# PIC32CM2532LS60048 register map
Vendor: Microchip Technology; Series: PIC32CMLS60; File version: 0
CPU: CM23 r0p0, selectable endian, MPU, no FPU, 2 interrupt priority bits
Registers are 32-bit, read-write, reset 0x0 unless marked. A register's access mark holds for its fields unless they carry their own. Offsets are from the block's base; [hi:lo] are bit positions; {n}, {i} and the like mark numbered series; 'fields as' and 'values as' point back to an identical list.

## CCL — Configurable Custom Logic
Base 0x42004800; register names take the prefix CCL_
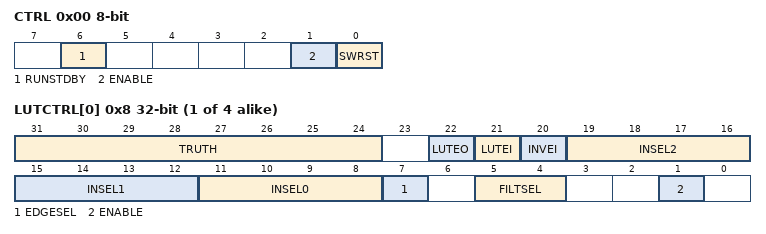
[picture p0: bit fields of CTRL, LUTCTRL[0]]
0x00 CTRL 8-bit — Control
  [6] RUNSTDBY — Run in Standby
    0=DISABLE (Generic clock is not required in standby sleep mode); 1=ENABLE (Generic clock is required in standby sleep mode)
  [1] ENABLE
    0=DISABLE (The peripheral is disabled); 1=ENABLE (The peripheral is enabled)
  [0] SWRST — Software Reset
    0=DISABLE (The peripheral is not reset); 1=ENABLE (The peripheral is reset)
{0x4+i} SEQCTRL[{i}] (i=0..1) 8-bit — SEQ Control x
  [3:0] SEQSEL — Sequential Selection
    0=DISABLE (Sequential logic is disabled); 1=DFF (D flip flop); 2=JK (JK flip flop); 3=LATCH (D latch); 4=RS (RS latch)
{0x8+4i} LUTCTRL[{i}] (i=0..3) — LUT Control x
  [31:24] TRUTH — Truth Value
  [22] LUTEO — LUT Event Output Enable
    0=DISABLE (LUT event output is disabled); 1=ENABLE (LUT event output is enabled)
  [21] LUTEI — LUT Event Input Enable
    0=DISABLE (LUT incoming event is disabled); 1=ENABLE (LUT incoming event is enabled)
  [20] INVEI — Inverted Event Input Enable
    0=NORMAL (Incoming event is not inverted); 1=INVERTED (Incoming event is inverted)
  [19:16] INSEL2 — Input Selection 2
    0=MASK (Masked input); 1=FEEDBACK (Feedback input source); 2=LINK (Linked LUT input source); 3=EVENT (Event input source); 4=IO (I/O pin input source); 5=AC (AC input source); 6=TC (TC input source); 7=ALTTC (Alternate TC input source); 8=TCC (TCC input source); 9=SERCOM (SERCOM input source); 11=ASYNCEVENT (Asynchronous event input source)
  [15:12] INSEL1 — Input Selection 1
    values as INSEL2
  [11:8] INSEL0 — Input Selection 0
    values as INSEL2
  [7] EDGESEL — Edge Selection
    0=DISABLE (Edge detector is disabled); 1=ENABLE (Edge detector is enabled)
  [5:4] FILTSEL — Filter Selection
    0=DISABLE (Filter disabled); 1=SYNCH (Synchronizer enabled); 2=FILTER (Filter enabled)
  [1] ENABLE — LUT Enable
    0=DISABLE (LUT block is disabled); 1=ENABLE (LUT block is enabled)

## CoreDebug — Debug Control Block
Base 0xE000EDF0; register names take the prefix CoreDebug_
Same registers: CoreDebug_NS 0xE002EDF0
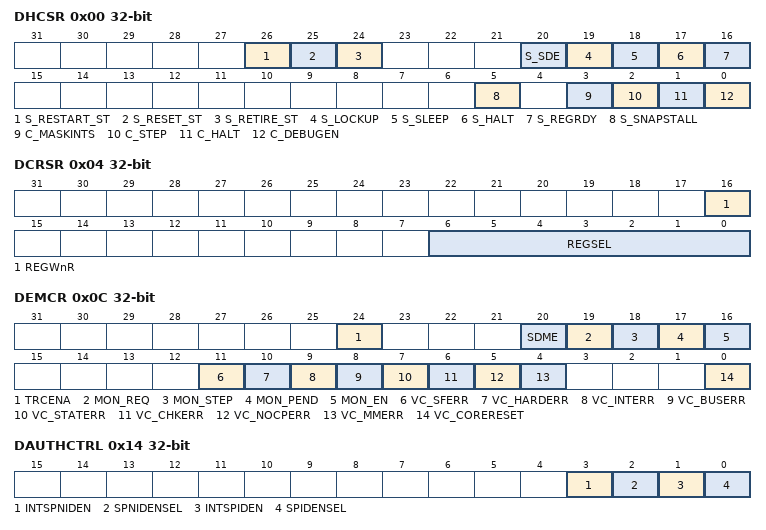
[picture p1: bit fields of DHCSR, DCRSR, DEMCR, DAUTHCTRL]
0x00 DHCSR — Debug Halting Control and Status Register
  [26] S_RESTART_ST — Restart sticky status
  [25] S_RESET_ST — Reset sticky status
  [24] S_RETIRE_ST — Retire sticky status
  [20] S_SDE — Secure debug enabled
  [19] S_LOCKUP — Lockup status
  [18] S_SLEEP — Sleeping status
  [17] S_HALT — Halted status
  [16] S_REGRDY — Register ready status
  [5] S_SNAPSTALL — Snap stall control
  [3] C_MASKINTS — Mask PendSV, SysTick and external configurable interrupts
  [2] C_STEP — Enable single step
  [1] C_HALT — Halt processor
  [0] C_DEBUGEN — Enable Halting debug
0x04 DCRSR wo — Debug Core Register Select Register
  [16] REGWnR — Register write/not-read access
  [6:0] REGSEL — Register selector
0x0C DEMCR — Debug Exception and Monitor Control Register
  [24] TRCENA — Global DWT and ITM features enable
  [20] SDME — Secure DebugMonitor enable
  [19] MON_REQ — DebugMonitor semaphore bit
  [18] MON_STEP — Enable DebugMonitor stepping
  [17] MON_PEND — DebugMonitor pending state
  [16] MON_EN — DebugMonitor enable
  [11] VC_SFERR — SecureFault exception Halting debug vector catch enable
  [10] VC_HARDERR — HardFault exception Halting debug vector catch enable
  [9] VC_INTERR — Excception entry and return faults Halting debug vector catch enable
  [8] VC_BUSERR — BusFault exception Halting debug vector catch enable
  [7] VC_STATERR — UsageFault exception state information error Halting debug vector catch enable
  [6] VC_CHKERR — UsageFault exception checking error Halting debug vector catch enable
  [5] VC_NOCPERR — UsageFault exception coprocessor access Halting debug vector catch enable
  [4] VC_MMERR — MemManage exception Halting debug vector catch enable
  [0] VC_CORERESET — Core reset Halting debug vector catch enable
0x14 DAUTHCTRL — Debug Authentication Control Register
  [3] INTSPNIDEN — Internal Secure non-invasive debug enable
  [2] SPNIDENSEL — Secure non-invasive debug enable select
  [1] INTSPIDEN — Internal Secure invasive debug enable
  [0] SPIDENSEL — Secure invasive debug enable select
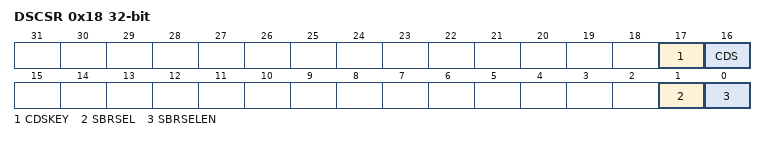
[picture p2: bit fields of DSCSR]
0x18 DSCSR — Debug Security Control and Status Register
  [17] CDSKEY — CDS field write-enable key
  [16] CDS — Current domain Secure
  [1] SBRSEL — Secure Banked register select
  [0] SBRSELEN — Secure Banked register select enable

## Notices in the file
Copyright (c) 2017 Microchip Technology Inc.
SPDX-License-Identifier: Apache-2.0
Licensed under the Apache License, Version 2.0 (the "License");
you may not use this file except in compliance with the License.
You may obtain a copy of the License at
http://www.apache.org/licenses/LICENSE-2.0
Unless required by applicable law or agreed to in writing, software
distributed under the License is distributed on an "AS IS" BASIS,
WITHOUT WARRANTIES OR CONDITIONS OF ANY KIND, either express or implied.
See the License for the specific language governing permissions and
limitations under the License.
